# AT90PWM316 device description
Architecture: AVR8; Family: megaAVR
Registers are 8-bit, access not given, no defined reset value unless marked. A register's access mark holds for its fields unless they carry their own. Offsets are from the block's base; [hi:lo] are bit positions; {n}, {i} and the like mark numbered series; 'fields as' and 'values as' point back to an identical list.

## PORTB — I/O Port
Instances: PORTB 0x00
0x23 PINB — Port B Input Pins
0x24 DDRB — Port B Data Direction Register
0x25 PORTB — Port B Data Register

## PORTC — I/O Port
Instances: PORTC 0x00
0x26 PINC — Port C Input Pins
0x27 DDRC — Port C Data Direction Register
0x28 PORTC — Port C Data Register

## PORTD — I/O Port
Instances: PORTD 0x00
0x29 PIND — Port D Input Pins
0x2A DDRD — Port D Data Direction Register
0x2B PORTD — Port D Data Register

## PORTE — I/O Port
Instances: PORTE 0x00
0x2C PINE bits used 2:0 — Port E Input Pins
0x2D DDRE bits used 2:0 — Port E Data Direction Register
0x2E PORTE bits used 2:0 — Port E Data Register

## BOOT_LOAD — Bootloader
Instances: BOOT_LOAD 0x00
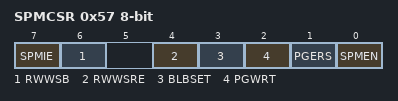
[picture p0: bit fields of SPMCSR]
0x57 SPMCSR — Store Program Memory Control Register
  [7] SPMIE — SPM Interrupt Enable
  [6] RWWSB — Read While Write Section Busy
  [4] RWWSRE — Read While Write section read enable
  [3] BLBSET — Boot Lock Bit Set
  [2] PGWRT — Page Write
  [1] PGERS — Page Erase
  [0] SPMEN — Store Program Memory Enable

## EUSART — Extended USART
Instances: EUSART 0x00
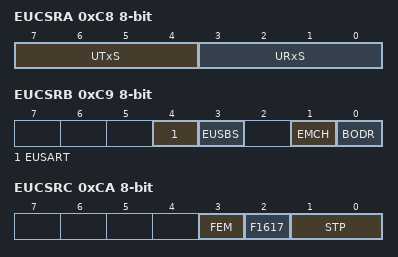
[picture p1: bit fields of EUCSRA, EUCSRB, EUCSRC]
0xC8 EUCSRA — EUSART Control and Status Register A
  [7:4] UTxS — EUSART Control and Status Register A Bits
    {v}={v+5}-bit (v=0..3); 7=9-bit; {v}={v+5}-bit (v=8..11); 15=17-bit
  [3:0] URxS — EUSART Control and Status Register A Bits
    {v}={v+5}-bit (v=0..3); 7=9-bit; {v}={v+5}-bit (v=8..11); 14=16 or 17; 15=17-bit
0xC9 EUCSRB — EUSART Control Register B
  [4] EUSART — EUSART Enable Bit
  [3] EUSBS — EUSBS Enable Bit
  [1] EMCH — Manchester Mode Bit
  [0] BODR — Order Bit
0xCA EUCSRC — EUSART Status Register C
  [3] FEM — Frame Error Manchester Bit
  [2] F1617 — F1617 Bit
  [1:0] STP — Stop Bits
0xCC MUBRRL — Manchester Receiver Baud Rate Register Low Byte
  [7:0] MUBRR — Manchester Receiver Baud Rate Register Bits
0xCD MUBRRH — Manchester Receiver Baud Rate Register High Byte
  [7:0] MUBRR (bit 8 of the value upward) — Manchester Receiver Baud Rate Register Bits
0xCE EUDR — EUSART I/O Data Register

## AC — Analog Comparator
Instances: AC 0x00
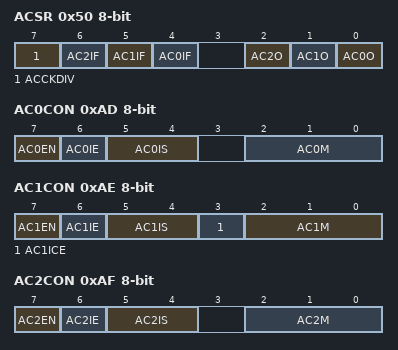
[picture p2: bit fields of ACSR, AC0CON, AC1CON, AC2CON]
0x50 ACSR — Analog Comparator Status Register
  [7] ACCKDIV — Analog Comparator Clock Divider
  [6] AC2IF — Analog Comparator 2 Interrupt Flag Bit
  [5] AC1IF — Analog Comparator 1 Interrupt Flag Bit
  [4] AC0IF — Analog Comparator 0 Interrupt Flag Bit
  [2] AC2O — Analog Comparator 2 Output Bit
  [1] AC1O — Analog Comparator 1 Output Bit
  [0] AC0O — Analog Comparator 0 Output Bit
0xAD AC0CON — Analog Comparator 0 Control Register
  [7] AC0EN — Analog Comparator 0 Enable Bit
  [6] AC0IE — Analog Comparator 0 Interrupt Enable Bit
  [5:4] AC0IS — Analog Comparator 0 Interrupt Select Bit
  [2:0] AC0M — Analog Comparator 0 Multiplexer Register
0xAE AC1CON — Analog Comparator 1 Control Register
  [7] AC1EN — Analog Comparator 1 Enable Bit
  [6] AC1IE — Analog Comparator 1 Interrupt Enable Bit
  [5:4] AC1IS — Analog Comparator 1 Interrupt Select Bit
    0=Interrupt on Toggle; 2=Interrupt on Falling Edge; 3=Interrupt on Rising Edge
  [3] AC1ICE — Analog Comparator 1 Interrupt Capture Enable Bit
  [2:0] AC1M — Analog Comparator 1 Multiplexer Register
0xAF AC2CON — Analog Comparator 2 Control Register
  [7] AC2EN — Analog Comparator 2 Enable Bit
  [6] AC2IE — Analog Comparator 2 Interrupt Enable Bit
  [5:4] AC2IS — Analog Comparator 2 Interrupt Select Bit
    values as AC1CON.AC1IS
  [2:0] AC2M — Analog Comparator 2 Multiplexer Register

## DAC — Digital-to-Analog Converter
Instances: DAC 0x00
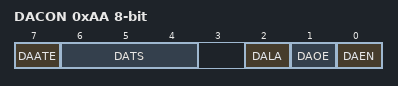
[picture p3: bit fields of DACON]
0xAA DACON — DAC Control Register
  [7] DAATE — DAC Auto Trigger Enable Bit
  [6:4] DATS — DAC Trigger Selection Bits
    0=Analog Comparator 0; 1=Analog Comparator 1; 2=External Interrupt Request 0; 3=Timer/Counter0 Compare Match A; 4=Timer/Counter0 Overflow; 5=Timer/Counter1 Compare Match B; 6=Timer/Counter1 Overflow; 7=Timer/Counter1 Capture Event
  [2] DALA — DAC Left Adjust
  [1] DAOE — DAC Output Enable
  [0] DAEN — DAC Enable Bit
0xAB DAC 16-bit — DAC Data Register Bytes
  [15:0] DAC — DAC Data Register Bits
